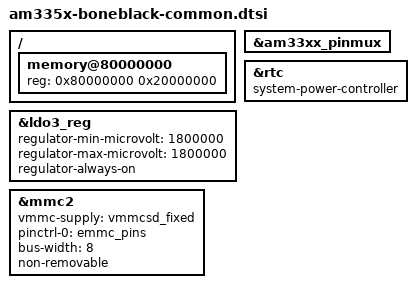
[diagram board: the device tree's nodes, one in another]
// SPDX-License-Identifier: GPL-2.0-only
/*
 * Copyright (C) 2012 Texas Instruments Incorporated - https://www.ti.com/
 */

#include <dt-bindings/display/tda998x.h>
#include <dt-bindings/interrupt-controller/irq.h>

&ldo3_reg {
	regulator-min-microvolt = <1800000>;
	regulator-max-microvolt = <1800000>;
	regulator-always-on;
};

// &mmc1 {
// 	vmmc-supply = <&vmmcsd_fixed>;
// };

&mmc2 {
	vmmc-supply = <&vmmcsd_fixed>;
	pinctrl-names = "default";
	pinctrl-0 = <&emmc_pins>;
	bus-width = <8>;
	status = "okay";
	non-removable;
};

&am33xx_pinmux {

};



&rtc {
	system-power-controller;
};


/ {
	memory@80000000 {
		device_type = "memory";
		reg = <0x80000000 0x20000000>; /* 512 MB */
	};


};
